# MSPM0G320X register map
Vendor: Texas Instruments; File version: Revised: 2025-10-06 10:58:04
CPU: CM0 r0p1, little endian, MPU, no FPU, 3 interrupt priority bits
Registers are 32-bit, read-write, reset 0x0 unless marked. A register's access mark holds for its fields unless they carry their own. Offsets are from the block's base; [hi:lo] are bit positions; lines under a group give offsets from that group; {n}, {i} and the like mark numbered series; 'fields as' and 'values as' point back to an identical list.

## EVENTLP — PERIPHERALREGION
Base 0x400C9000
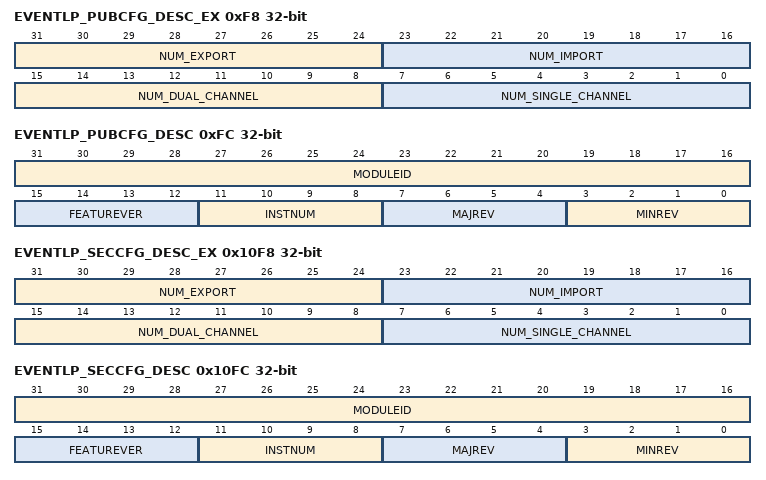
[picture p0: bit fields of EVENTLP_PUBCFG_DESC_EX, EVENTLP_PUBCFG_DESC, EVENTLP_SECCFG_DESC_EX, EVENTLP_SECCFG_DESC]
0xF8 EVENTLP_PUBCFG_DESC_EX ro — Extended Module Description
  [31:24] NUM_EXPORT — Number of export ports available in this EventManager instantiation
  [23:16] NUM_IMPORT — Number of import ports available in this EventManager instantiation
  [15:8] NUM_DUAL_CHANNEL — Number of dual channels contained in this instance of event manager
  [7:0] NUM_SINGLE_CHANNEL — Number of single channels contained in this instance of event manager
0xFC EVENTLP_PUBCFG_DESC ro — Module Description
  [31:16] MODULEID — Module identification contains a unique peripheral identification number. The assignments are maintained in a central database for all of the platform modules to ensure uniqueness.
  [15:12] FEATUREVER — Feature Set for the module *instance*
  [11:8] INSTNUM — Instance Number within the device. This will be a parameter to the RTL for modules that can have multiple instances
  [7:4] MAJREV — Major rev of the IP
  [3:0] MINREV — Minor rev of the IP
0x100 EVENTLP_PUBCFG_FSUB[{i}] (i=0..0; step 0x0) group
  0x00 EVENTLP_PUBCFG_FSUB_PORT — Subscriber channel ID register
    [7:0] CHANID — Channel ID for subscriber to connect to
0x300 EVENTLP_PUBCFG_FPUB[{i}] (i=0..0; step 0x0) group
  0x00 EVENTLP_PUBCFG_FPUB_PORT — Publisher channel ID register
    [7:0] CHANID — Channel ID for publisher to connect to
{0x500+4i} EVENTLP_PUBCFG_EXPORT[{i}] (i=0..0) group
  0x00 EVENTLP_PUBCFG_EXPORT_PORT — Export channel ID register
    [7:0] CHANID — Channel ID for export side to connect to
{0x700+4i} EVENTLP_PUBCFG_IMPORT[{i}] (i=0..0) group
  0x00 EVENTLP_PUBCFG_IMPORT_PORT — Import channel ID registe
    [7:0] CHANID — Channel ID for import side to connect to
0x900 EVENTLP_PUBCFG_CPU_CONNECT[{i}] (i=0..0; step 0x0) group
  0x00 EVENTLP_PUBCFG_CPU_NUM — CPU connect register
0x10F8 EVENTLP_SECCFG_DESC_EX ro — Extended Module Description
  fields as EVENTLP_PUBCFG_DESC_EX
0x10FC EVENTLP_SECCFG_DESC ro — Module Description
  fields as EVENTLP_PUBCFG_DESC
0x1100 EVENTLP_SECCFG_FSUB[{i}] (i=0..0; step 0x0) group
  0x00 EVENTLP_SECCFG_FSUB_PORT 8-bit — Subscriber channel ID register
    [7:0] CHANID — Channel ID for subscriber to connect to
0x1180 EVENTLP_SECCFG_FPUB[{i}] (i=0..0; step 0x0) group
  0x00 EVENTLP_SECCFG_FPUB_PORT 8-bit — Publisher channel ID register
    [7:0] CHANID — Channel ID for publisher to connect to
{0x1200+i} EVENTLP_SECCFG_EXPORT[{i}] (i=0..0) group
  0x00 EVENTLP_SECCFG_EXPORT_PORT 8-bit — Export channel ID register
    [7:0] CHANID — Channel ID for export side to connect to
{0x1280+i} EVENTLP_SECCFG_IMPORT[{i}] (i=0..0) group
  0x00 EVENTLP_SECCFG_IMPORT_PORT 8-bit — Import channel ID registe
    [7:0] CHANID — Channel ID for import side to connect to
0x1300 EVENTLP_SECCFG_CPU_CONNECT[{i}] (i=0..0; step 0x0) group
  0x00 EVENTLP_SECCFG_CPU_NUM 8-bit — CPU connect register
0x1400 EVENTLP_CTL 8-bit — Event Manager control register
  [3:0] OVRWR_EN — Enable overwrite of config even if resources are already configured. By default, a configuration cannot be overwritten.
    5=DISABLE (Overwrite is disabled. Mode is same as in UNASG aperture.); 10=ENABLED (Ovewrite is enabled)
{0x2000+4i} EVENTLP_IMPEXPCFG_EXPORT[{i}] (i=0..0) group
  0x00 EVENTLP_IMPEXPCFG_EXPORT_PORT — Export channel ID register
    [7:0] CHANID — Channel ID for import side to connect to
{0x2200+4i} EVENTLP_IMPEXPCFG_IMPORT[{i}] (i=0..0) group
  0x00 EVENTLP_IMPEXPCFG_IMPORT_PORT — Import channel ID registe
    [7:0] CHANID — Channel ID for import side to connect to

## UC4 — PERIPHERALREGION
Base 0x40A84000
{0x800+0x18*i} UC4_GPRCM[{i}] (i=0..0) group
  0x00 UC4_PWREN — Power enable
    [0] ENABLE — Enable the power
      0=DISABLE (Disable Power); 1=ENABLE (Enable Power)
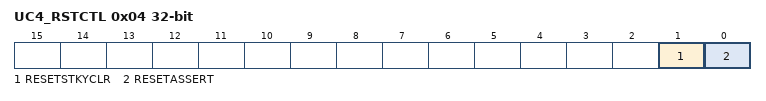
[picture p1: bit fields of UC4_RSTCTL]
  0x04 UC4_RSTCTL wo — Reset Control
    [1] RESETSTKYCLR — Clear the RESETSTKY bit in the STAT register
      0=NOP (Writing 0 has no effect); 1=CLR (Clear reset sticky bit)
    [0] RESETASSERT — Assert reset to the peripheral
      0=NOP (Writing 0 has no effect); 1=ASSERT (Assert reset)
  0x08 UC4_CLKCFG — Peripheral Clock Configuration Register
    [8] BLOCKASYNC — Async Clock Request is blocked from starting SYSOSC or forcing bus clock to 32MHz
      0=DISABLE (Not block async clock request); 1=ENABLE (Block async clock request)
  0x14 UC4_GPRCM_STAT ro — Status Register
    [16] RESETSTKY — This bit indicates, if the peripheral was reset, since this bit was cleared by RESETSTKYCLR in the RSTCTL register
      0=NORES (The peripheral has not been reset since this bit was last cleared by RESETSTKYCLR in the RSTCTL register); 1=RESET (The peripheral was reset since the last bit clear)
0x1100 UC4_IPMODE — Mode Selection Register
  [1:0] SELECT — Free run control
    0=UART (Default functionality is UART); 1=SPI (SPG in SPI Mode); 2=I2C_CONTROLLER (SPG in I2C Controller Mode); 3=I2C_PERIPHERAL (SPG in I2C Peripheral Mode)

## UC0 — PERIPHERALREGION
Base 0x40A86000
Registers as UC4 (with UC4 read as UC0).

## UC5 — PERIPHERALREGION
Base 0x40A88000
Registers as UC4 (with UC4 read as UC5).

## UC2 — PERIPHERALREGION
Base 0x40B80000
Registers as UC4 (with UC4 read as UC2), without UC4_IPMODE.

## UC9 — PERIPHERALREGION
Base 0x40B84000
Registers as UC4 (with UC4 read as UC9), without UC4_IPMODE.
